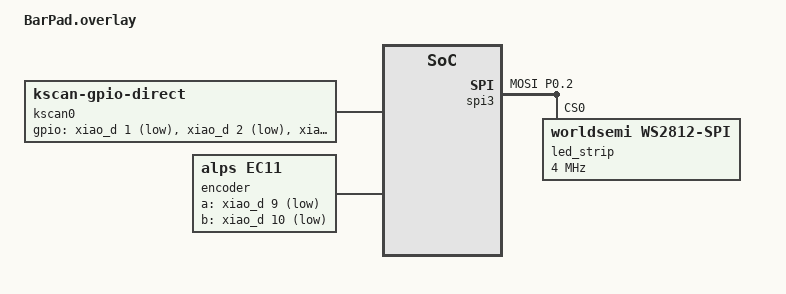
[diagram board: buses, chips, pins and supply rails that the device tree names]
#include <dt-bindings/zmk/matrix_transform.h>

/ {
    chosen {
        zmk,kscan = &kscan0;
        zmk,underglow = &led_strip;
    };

    kscan0: kscan {
        compatible = "zmk,kscan-gpio-direct";
        wakeup-source;
        gpios =
            <&xiao_d 1 (GPIO_ACTIVE_LOW | GPIO_PULL_UP)>,
            <&xiao_d 2 (GPIO_ACTIVE_LOW | GPIO_PULL_UP)>,
            <&xiao_d 3 (GPIO_ACTIVE_LOW | GPIO_PULL_UP)>,
            <&xiao_d 4 (GPIO_ACTIVE_LOW | GPIO_PULL_UP)>,
            <&xiao_d 5 (GPIO_ACTIVE_LOW | GPIO_PULL_UP)>,
            <&xiao_d 6 (GPIO_ACTIVE_LOW | GPIO_PULL_UP)>,
            <&xiao_d 7 (GPIO_ACTIVE_LOW | GPIO_PULL_UP)>,
            <&xiao_d 8 (GPIO_ACTIVE_LOW | GPIO_PULL_UP)>;
    };

    encoder: encoder {
        compatible = "alps,ec11";
        a-gpios = <&xiao_d 9 (GPIO_ACTIVE_LOW | GPIO_PULL_UP)>;
        b-gpios = <&xiao_d 10 (GPIO_ACTIVE_LOW | GPIO_PULL_UP)>;
        steps = <24>;
        status = "okay";
    };

    sensors: sensors {
        compatible = "zmk,keymap-sensors";
        sensors = <&encoder>;
        triggers-per-rotation = <12>;
    };
};

&pinctrl {
    spi3_default: spi3_default {
        group1 { psels = <NRF_PSEL(SPIM_MOSI, 0, 2)>; };
    };
    spi3_sleep: spi3_sleep {
        group1 { psels = <NRF_PSEL(SPIM_MOSI, 0, 2)>; low-power-enable; };
    };
};

&spi3 {
    compatible = "nordic,nrf-spim";
    status = "okay";
    pinctrl-0 = <&spi3_default>;
    pinctrl-1 = <&spi3_sleep>;

    led_strip: ws2812@0 {
        compatible = "worldsemi,ws2812-spi";
        reg = <0>;
        spi-max-frequency = <4000000>;
        chain-length = <8>;
        spi-one-frame = <0x70>;
        spi-zero-frame = <0x40>;
        color-mapping = <LED_COLOR_ID_GREEN LED_COLOR_ID_RED LED_COLOR_ID_BLUE>;
    };
};
